# BlueNRG_LPS register map
File version: 1.0
CPU: CM0+ r0p0, little endian, no MPU, no FPU, 2 interrupt priority bits
Registers are 32-bit, read-write, reset 0x0 unless marked. A register's access mark holds for its fields unless they carry their own. Offsets are from the block's base; [hi:lo] are bit positions; {n}, {i} and the like mark numbered series.

## ADC
Base 0x41006000
0x00 VERSION_ID ro reset 0x20
  [7:0] VERSION_ID — version of the embedded IP.
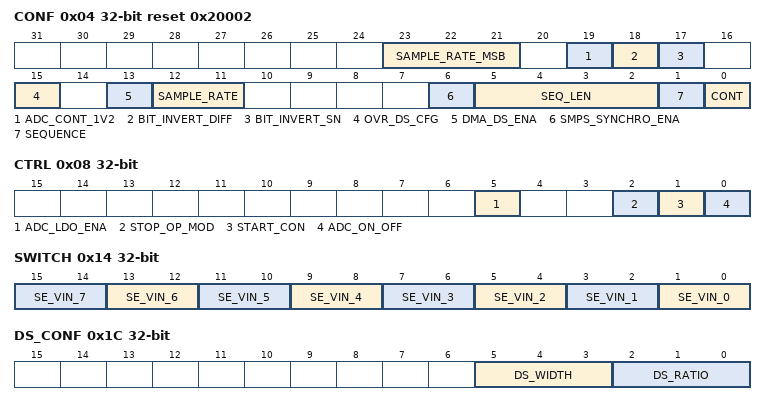
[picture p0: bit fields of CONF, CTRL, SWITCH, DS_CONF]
0x04 CONF reset 0x20002 — ADC configuration register
  [23:21] SAMPLE_RATE_MSB — sample rate most significant bit
  [19] ADC_CONT_1V2 — select the input sampling method
  [18] BIT_INVERT_DIFF — invert bit to bit the ADC data output when a differential
  [17] BIT_INVERT_SN — invert bit to bit the ADC data output when a single
  [15] OVR_DS_CFG — Down Sampler overrun configuration
  [13] DMA_DS_ENA — enable DMA mode for Down Sampler data path
  [12:11] SAMPLE_RATE — conversion rate of ADC
  [6] SMPS_SYNCHRO_ENA — synchronize the ADC start conversion with a pulse generated
  [5:2] SEQ_LEN — number of conversions in a regular sequence
  [1] SEQUENCE — enable the sequence mode (active by default)
  [0] CONT — regular sequence runs continuously when ADC mode is enabled
0x08 CTRL — ADC control register
  [5] ADC_LDO_ENA — enable the LDO associated to the ADC block
  [2] STOP_OP_MOD — stop the on-going OP_MODE (ADC mode, Analog audio mode, Full
  [1] START_CON — generate a start pulse to initiate an ADC conversion
  [0] ADC_ON_OFF
0x14 SWITCH — ADC switch control for Input Selection
  [2n+1:2n] SE_VIN_{n} (n=4..7) — input voltage for VINP[{n-4}]
  [2n+1:2n] SE_VIN_{n} (n=0..3) — input voltage for VINM[{n}] / VINP[{n}]-VINM[{n}]
0x1C DS_CONF — Downsampler configuration register
  [5:3] DS_WIDTH — program the Down Sampler width of data output (DSDTATA)
  [2:0] DS_RATIO — program the Down Sampler ratio (N factor)
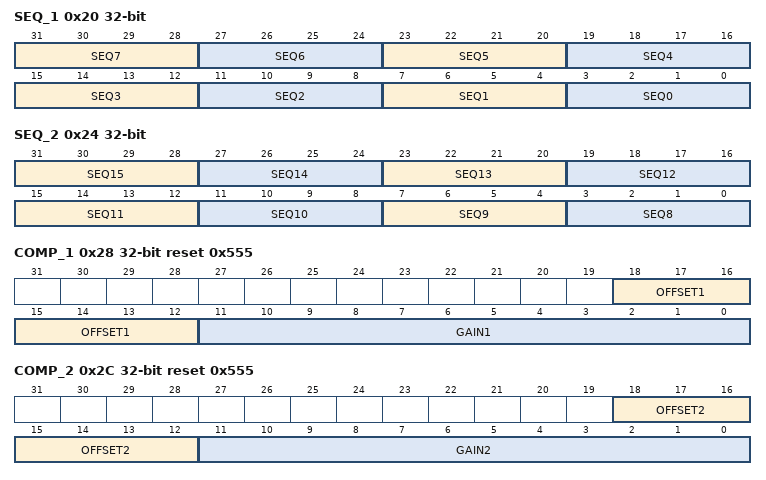
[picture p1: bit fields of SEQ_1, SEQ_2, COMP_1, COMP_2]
0x20 SEQ_1 — ADC regular sequence configuration register 1
  [4n+3:4n] SEQ{n} (n=3..7) — channel number code for {n+1}th conversion of the sequence.
  [11:8] SEQ2 — channel number code for 3rd conversion of the sequence.
  [7:4] SEQ1 — channel number code for second conversion of the sequence.
  [3:0] SEQ0 — channel number code for first conversion of the sequence
0x24 SEQ_2 — ADC regular sequence configuration register 2
  [4n-29:4n-32] SEQ{n} (n=9..15) — channel number code for {n+1}th conversion of the sequence.
  [3:0] SEQ8 — channel number code for 9th conversion of the sequence
0x28 COMP_1 reset 0x555 — ADC Gain and offset correction values register 1
  [18:12] OFFSET1 — first calibration point: signed offset compensation[6:0]
  [11:0] GAIN1 — first calibration point: gain AUXADC_GAIN_1V2[11:0]
0x2C COMP_2 reset 0x555 — ADC Gain and offset correction values register 2
  [18:12] OFFSET2 — second calibration point: signed offset compensation[6:0]
  [11:0] GAIN2 — second calibration point: gain AUXADC_GAIN_1V2[11:0]
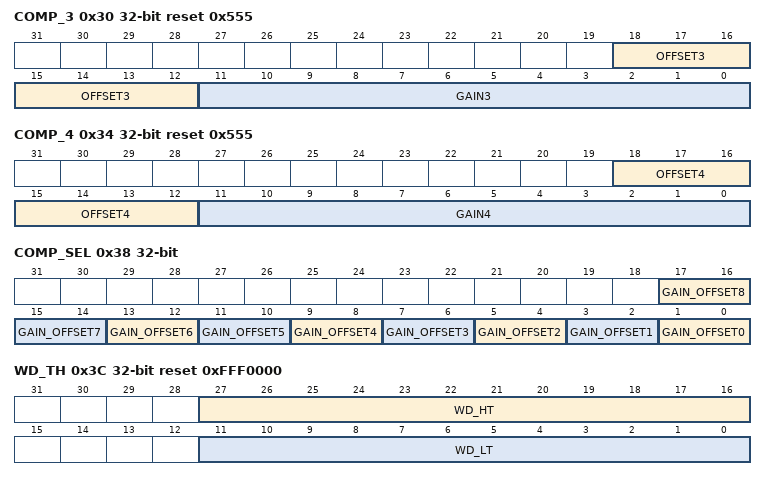
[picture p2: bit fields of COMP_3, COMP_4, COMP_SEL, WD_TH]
0x30 COMP_3 reset 0x555 — ADC Gain and offset correction values register 3
  [18:12] OFFSET3 — third calibration point: signed offset compensation[6:0]
  [11:0] GAIN3 — third calibration point: gain AUXADC_GAIN_1V2[11:0]
0x34 COMP_4 reset 0x555 — ADC Gain and offset correction values register 4
  [18:12] OFFSET4 — fourth calibration point: signed offset compensation[6:0]
  [11:0] GAIN4 — fourth calibration point: gain AUXADC_GAIN_1V2[11:0]
0x38 COMP_SEL — ADC Gain and Offset selection values register
  [17:16] GAIN_OFFSET8 — gain / offset used in ADC differential mode with Vinput range = 3.6V
  [15:14] GAIN_OFFSET7 — gain / offset used in ADC single positive mode with Vinput range = 3.6V
  [13:12] GAIN_OFFSET6 — gain / offset used in ADC single negative mode with Vinput range = 3.6V
  [11:10] GAIN_OFFSET5 — gain / offset used in ADC differential mode with Vinput range = 2.4V
  [9:8] GAIN_OFFSET4 — gain / offset used in ADC single positive mode with Vinput range = 2.4V
  [7:6] GAIN_OFFSET3 — gain / offset used in ADC single negative mode with Vinput range = 2.4V
  [5:4] GAIN_OFFSET2 — gain / offset used in ADC differential mode with Vinput range = 1.2V
  [3:2] GAIN_OFFSET1 — gain / offset used in ADC single positive mode with Vinput range = 1.2V
  [1:0] GAIN_OFFSET0 — gain / offset used in ADC single negative mode with Vinput range = 1.2V
0x3C WD_TH reset 0xFFF0000 — High/low limits for event monitoring a channel register
  [27:16] WD_HT — analog watchdog high level threshold.
  [11:0] WD_LT — analog watchdog low level threshold.
0x40 WD_CONF — Channel selection for event monitoring register
  [15:0] AWD_CHX — analog watchdog channel selection to define which input channel(s) need to be guarded by the watchdog.
0x44 DS_DATAOUT ro — Downsampler Data output register
  [15:0] DS_DATA — contain the converted data at the output of the Down Sampler
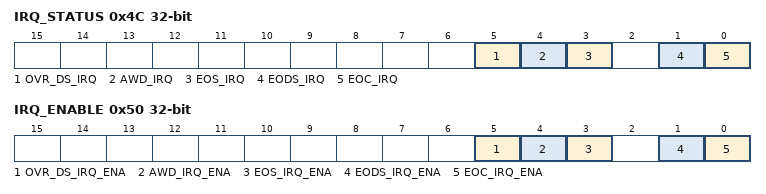
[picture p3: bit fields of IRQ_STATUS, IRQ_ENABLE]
0x4C IRQ_STATUS — Interrupt Status register
  [5] OVR_DS_IRQ — set to indicate a Down Sampler overrun (at least one data is lost)
  [4] AWD_IRQ — set when an analog watchdog event occurs
  [3] EOS_IRQ — set when a sequence of conversion is completed
  [1] EODS_IRQ — set when the Down Sampler conversion is completed.
  [0] EOC_IRQ — (Used in test mode only): set when the ADC conversion is completed.
0x50 IRQ_ENABLE — Enable/disable Interrupts
  [5] OVR_DS_IRQ_ENA — Down Sampler overrun interrupt enable
  [4] AWD_IRQ_ENA — analog watchdog interrupt enable
  [3] EOS_IRQ_ENA — End of regular sequence interrupt enable
  [1] EODS_IRQ_ENA — End of conversion interrupt enable for the Down Sampler output
  [0] EOC_IRQ_ENA — (Used in test mode only): End of ADC conversion interrupt enable
0x54 TIMER_CONF reset 0x28 — Time to add after an LDO Enable or ADC Enable to let the HW to be stable before using it
  [7:0] ADC_LDO_DELAY — define the duration of a waiting time to be inserted between the ADC_LDO enable and the ADC ON to let time to the LDO to stabilize before starting a conversion.
